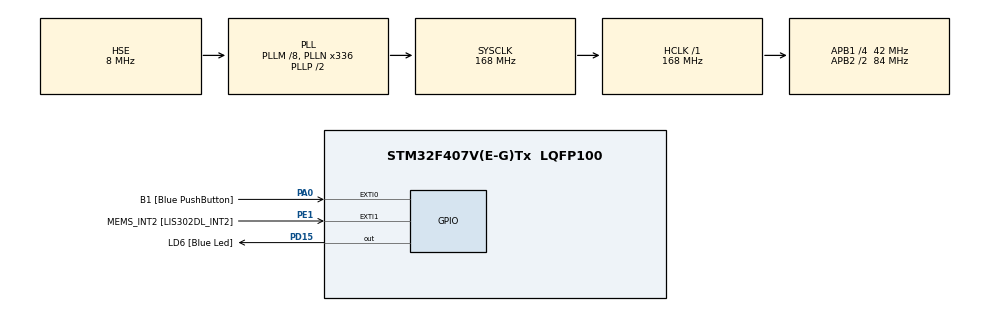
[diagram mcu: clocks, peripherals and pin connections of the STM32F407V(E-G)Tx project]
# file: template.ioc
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FREERTOS.Tasks01=defaultTask,0,128,StartDefaultTask,Default,NULL
Mcu.Family=STM32F4
Mcu.Name=STM32F407V(E-G)Tx
Mcu.Package=LQFP100
NVIC.PriorityGroup=NVIC_PRIORITYGROUP_4
PA0-WKUP.GPIO_Label=B1 [Blue PushButton]
PA0-WKUP.GPIO_ModeDefaultEXTI=GPIO_MODE_EVT_RISING
PA0-WKUP.GPIO_PuPd=GPIO_NOPULL
PA0-WKUP.Signal=GPXTI0
PA13.GPIO_Label=SWDIO
PA13.Mode=Trace_Asynchronous_SW
PA13.Signal=SYS_JTMS-SWDIO
PA14.GPIO_Label=SWCLK
PA14.Mode=Trace_Asynchronous_SW
PA14.Signal=SYS_JTCK-SWCLK
PB3.GPIO_Label=SWO
PB3.Mode=Trace_Asynchronous_SW
PB3.Signal=SYS_JTDO-SWO
PB8.Signal=CAN1_RX
PB9.Signal=CAN1_TX
PC14-OSC32_IN.GPIO_Label=PC14-OSC32_IN
PC14-OSC32_IN.Mode=LSE-External-Oscillator
PC14-OSC32_IN.Signal=RCC_OSC32_IN
PC15-OSC32_OUT.GPIO_Label=PC15-OSC32_OUT
PC15-OSC32_OUT.Mode=LSE-External-Oscillator
PC15-OSC32_OUT.Signal=RCC_OSC32_OUT
PD15.GPIO_Label=LD6 [Blue Led]
PD15.GPIO_PuPd=GPIO_NOPULL
PD15.GPIO_Speed=GPIO_SPEED_FREQ_LOW
PD15.Signal=GPIO_Output
PE1.GPIO_Label=MEMS_INT2 [LIS302DL_INT2]
PE1.GPIO_ModeDefaultEXTI=GPIO_MODE_EVT_RISING
PE1.GPIO_PuPd=GPIO_NOPULL
PE1.Signal=GPXTI1
PH0-OSC_IN.GPIO_Label=PH0-OSC_IN
PH0-OSC_IN.Mode=HSE-External-Oscillator
PH0-OSC_IN.Signal=RCC_OSC_IN
PH1-OSC_OUT.GPIO_Label=PH1-OSC_OUT
PH1-OSC_OUT.Mode=HSE-External-Oscillator
PH1-OSC_OUT.Signal=RCC_OSC_OUT
ProjectManager.HeapSize=0x200
ProjectManager.StackSize=0x400
ProjectManager.TargetToolchain=Makefile
RCC.48MHZClocksFreq_Value=48000000
RCC.AHBFreq_Value=168000000
RCC.APB1CLKDivider=RCC_HCLK_DIV4
RCC.APB1Freq_Value=42000000
RCC.APB1TimFreq_Value=84000000
RCC.APB2CLKDivider=RCC_HCLK_DIV2
RCC.APB2Freq_Value=84000000
RCC.APB2TimFreq_Value=168000000
RCC.CortexFreq_Value=168000000
RCC.HCLKFreq_Value=168000000
RCC.HSE_VALUE=8000000
RCC.HSI_VALUE=16000000
RCC.PLLM=8
RCC.PLLN=336
RCC.PLLQ=7
RCC.PLLSourceVirtual=RCC_PLLSOURCE_HSE
RCC.SYSCLKFreq_VALUE=168000000
RCC.SYSCLKSource=RCC_SYSCLKSOURCE_PLLCLK
RCC.VCOOutputFreq_Value=336000000
VP_FREERTOS_VS_CMSIS_V1.Mode=CMSIS_V1
board=STM32F4DISCOVERY

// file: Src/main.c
/* USER CODE BEGIN Header */
/**
  ******************************************************************************
  * @file           : main.c
  * @brief          : Main program body
  ******************************************************************************
  * @attention
  *
  * <h2><center>&copy; Copyright (c) 2019 STMicroelectronics.
  * All rights reserved.</center></h2>
  *
  * This software component is licensed by ST under Ultimate Liberty license
  * SLA0044, the "License"; You may not use this file except in compliance with
  * the License. You may obtain a copy of the License at:
  *                             www.st.com/SLA0044
  *
  ******************************************************************************
  */
/* USER CODE END Header */

#include "main.h"
#include "cmsis_os.h"
#include "gpio.h"

void SystemClock_Config(void);
void MX_FREERTOS_Init(void);

int main(void)
{

  /* MCU Configuration--------------------------------------------------------*/

  /* Reset of all peripherals, Initializes the Flash interface and the Systick. */
  HAL_Init();

  /* Configure the system clock */
  SystemClock_Config();

  /* Initialize all configured peripherals */
  MX_GPIO_Init();

  /* Call init function for freertos objects (in freertos.c) */
  MX_FREERTOS_Init();

  /* Start scheduler */
  osKernelStart();

  /* We should never get here as control is now taken by the scheduler */

  /* Infinite loop */
  while (1)
  {

  }
}

void SystemClock_Config(void)
{
  RCC_OscInitTypeDef RCC_OscInitStruct = {0};
  RCC_ClkInitTypeDef RCC_ClkInitStruct = {0};

  /** Configure the main internal regulator output voltage
  */
  __HAL_RCC_PWR_CLK_ENABLE();
  __HAL_PWR_VOLTAGESCALING_CONFIG(PWR_REGULATOR_VOLTAGE_SCALE1);
  /** Initializes the CPU, AHB and APB busses clocks
  */
  RCC_OscInitStruct.OscillatorType = RCC_OSCILLATORTYPE_HSE;
  RCC_OscInitStruct.HSEState = RCC_HSE_ON;
  RCC_OscInitStruct.PLL.PLLState = RCC_PLL_ON;
  RCC_OscInitStruct.PLL.PLLSource = RCC_PLLSOURCE_HSE;
  RCC_OscInitStruct.PLL.PLLM = 8;
  RCC_OscInitStruct.PLL.PLLN = 336;
  RCC_OscInitStruct.PLL.PLLP = RCC_PLLP_DIV2;
  RCC_OscInitStruct.PLL.PLLQ = 7;
  if (HAL_RCC_OscConfig(&RCC_OscInitStruct) != HAL_OK)
  {
    Error_Handler();
  }
  /** Initializes the CPU, AHB and APB busses clocks
  */
  RCC_ClkInitStruct.ClockType = RCC_CLOCKTYPE_HCLK|RCC_CLOCKTYPE_SYSCLK
                              |RCC_CLOCKTYPE_PCLK1|RCC_CLOCKTYPE_PCLK2;
  RCC_ClkInitStruct.SYSCLKSource = RCC_SYSCLKSOURCE_PLLCLK;
  RCC_ClkInitStruct.AHBCLKDivider = RCC_SYSCLK_DIV1;
  RCC_ClkInitStruct.APB1CLKDivider = RCC_HCLK_DIV4;
  RCC_ClkInitStruct.APB2CLKDivider = RCC_HCLK_DIV2;

  if (HAL_RCC_ClockConfig(&RCC_ClkInitStruct, FLASH_LATENCY_5) != HAL_OK)
  {
    Error_Handler();
  }
}

void Error_Handler(void)
{
}

/************************ (C) COPYRIGHT STMicroelectronics *****END OF FILE****/

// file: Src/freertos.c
/* USER CODE BEGIN Header */
/**
  ******************************************************************************
  * File Name          : freertos.c
  * Description        : Code for freertos applications
  ******************************************************************************
  * @attention
  *
  * <h2><center>&copy; Copyright (c) 2019 STMicroelectronics.
  * All rights reserved.</center></h2>
  *
  * This software component is licensed by ST under Ultimate Liberty license
  * SLA0044, the "License"; You may not use this file except in compliance with
  * the License. You may obtain a copy of the License at:
  *                             www.st.com/SLA0044
  *
  ******************************************************************************
  */
/* USER CODE END Header */

#include "FreeRTOS.h"
#include "task.h"
#include "main.h"
#include "cmsis_os.h"

/* USER CODE BEGIN Includes */
#include "APP_heartBeat.h"
/* USER CODE END Includes */

/* USER CODE BEGIN Variables */
osThreadId tsk_heartBeatID;
/* USER CODE END Variables */
osThreadId defaultTaskHandle;

void StartDefaultTask(void const * argument);

void MX_FREERTOS_Init(void); /* (MISRA C 2004 rule 8.1) */

void MX_FREERTOS_Init(void) {

  /* Create the thread(s) */
  /* definition and creation of defaultTask */
  osThreadDef(defaultTask, StartDefaultTask, osPriorityNormal, 0, 128);
  defaultTaskHandle = osThreadCreate(osThread(defaultTask), NULL);

  /* USER CODE BEGIN RTOS_THREADS */
  osThreadDef(heartBeat,tsk_heartBeat,osPriorityLow,1,100);
  tsk_heartBeatID = osThreadCreate(osThread(heartBeat),0);
  /* USER CODE END RTOS_THREADS */

}

void StartDefaultTask(void const * argument)
{

  for(;;)
  {
    osDelay(1);
  }
}

/************************ (C) COPYRIGHT STMicroelectronics *****END OF FILE****/
